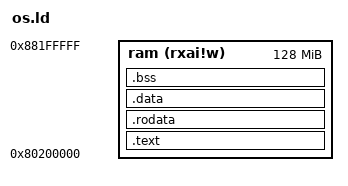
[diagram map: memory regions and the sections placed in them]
OUTPUT_ARCH(riscv)
ENTRY(_start)
BASE_ADDRESS = 0x80200000;
MEMORY
{
	ram (rxai!w) : ORIGIN = 0x80200000, LENGTH = 128M
}
PHDRS
{
	text PT_LOAD FLAGS(5);
	data PT_LOAD FLAGS(6);
}
SECTIONS
{
    skernel = .;   /* 定义内核起始内存地址 */
	.text : {
        *(.text.entry)
        . = ALIGN(4K);
        trampoline = .;
        *(.text.trampoline);
        . = ALIGN(4K);
		_strampoline = .;
		*(.text .text.*)
		. = ALIGN(4K);
		PROVIDE(etext = .);
	} >ram :text



	.rodata : {
		*(.rodata .rodata.*)
		. = ALIGN(4K);
	} >ram :text



	.data : {
		*(.sdata .sdata.*)
		*(.data .data.*)
		. = ALIGN(4K);
		PROVIDE(_data_end = .);
	} >ram :data

	.bss :{
		*(.sbss .sbss.*)
		*(.bss .bss.*)
		*(COMMON)
		. = ALIGN(4K);
	} >ram :data



	PROVIDE(kernelend = .);
}
